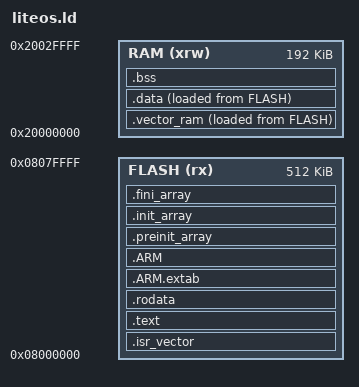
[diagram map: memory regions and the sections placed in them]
/*
******************************************************************************
**
**  File        : LinkerScript.ld
**
**  Author      : STM32CubeIDE
**
**  Abstract    : Linker script for STM32L552xE Device from STM32L5 series
**                      512Kbytes FLASH
**                      192Kbytes RAM
**
**                Set heap size, stack size and stack location according
**                to application requirements.
**
**                Set memory bank area and size if external memory is used.
**
**  Target      : STMicroelectronics STM32
**
**  Distribution: The file is distributed as is without any warranty
**                of any kind.
**
*****************************************************************************
** @attention
**
** <h2><center>&copy; Copyright (c) 2020 STMicroelectronics.
** All rights reserved.</center></h2>
**
** This software component is licensed by ST under BSD 3-Clause license,
** the "License"; You may not use this file except in compliance with the
** License. You may obtain a copy of the License at:
**                        opensource.org/licenses/BSD-3-Clause
**
*****************************************************************************
*/

/* Entry Point */
ENTRY(Reset_Handler)

/* Highest address of the user mode stack */
_estack = ORIGIN(RAM) + LENGTH(RAM);  /* end of "RAM" Ram type memory */

_Min_Stack_Size = 0x400;    /* required amount of stack */

/* Memories definition */
MEMORY
{
  RAM (xrw) : ORIGIN = 0x20000000,  LENGTH = 192K
  FLASH (rx)  : ORIGIN = 0x8000000, LENGTH = 512K
}

/* Sections */
SECTIONS
{
  /* The startup code into "FLASH" Rom type memory */
  .isr_vector :
  {
    . = ALIGN(4);
    KEEP(*(.isr_vector)) /* Startup code */
    . = ALIGN(4);
  } >FLASH

  /* The program code and other data into "FLASH" Rom type memory */
  .text :
  {
    . = ALIGN(4);
    __text_start = .;
    *(.text)           /* .text sections (code) */
    *(.text*)          /* .text* sections (code) */
    *(.glue_7)         /* glue arm to thumb code */
    *(.glue_7t)        /* glue thumb to arm code */
    *(.eh_frame)

    KEEP (*(.init))
    KEEP (*(.fini))

    . = ALIGN(4);
    _etext = .;        /* define a global symbols at end of code */
    __text_end = _etext;
  } >FLASH

  /* Constant data into "FLASH" Rom type memory */
  .rodata :
  {
    . = ALIGN(4);
    __rodata_start = .;

    *(.rodata)         /* .rodata sections (constants, strings, etc.) */
    *(.rodata*)        /* .rodata* sections (constants, strings, etc.) */
    . = ALIGN(4);
    __rodata_end = .;
  } >FLASH

  .ARM.extab   : {
    . = ALIGN(4);
    *(.ARM.extab* .gnu.linkonce.armextab.*)
    . = ALIGN(4);
  } >FLASH

  .ARM : {
    . = ALIGN(4);
    __exidx_start = .;
    *(.ARM.exidx*)
    __exidx_end = .;
    . = ALIGN(4);
  } >FLASH

  .preinit_array     :
  {
    . = ALIGN(4);
    PROVIDE_HIDDEN (__preinit_array_start = .);
    KEEP (*(.preinit_array*))
    PROVIDE_HIDDEN (__preinit_array_end = .);
    . = ALIGN(4);
  } >FLASH

  .init_array :
  {
    . = ALIGN(4);
    PROVIDE_HIDDEN (__init_array_start = .);
    KEEP (*(SORT(.init_array.*)))
    KEEP (*(.init_array*))
    PROVIDE_HIDDEN (__init_array_end = .);
    . = ALIGN(4);
  } >FLASH

  .fini_array :
  {
    . = ALIGN(4);
    PROVIDE_HIDDEN (__fini_array_start = .);
    KEEP (*(SORT(.fini_array.*)))
    KEEP (*(.fini_array*))
    PROVIDE_HIDDEN (__fini_array_end = .);
    . = ALIGN(4);
  } >FLASH

  /* used by the startup to initialize liteos vector */
  _si_liteos_vector_data = LOADADDR(.vector_ram);

  /* Initialized liteos vector sections goes into RAM, load LMA copy after code */
  .vector_ram :
  {
    . = ORIGIN(RAM);
    _s_liteos_vector = .;
    *(.data.vector)    /* liteos vector in ram */
    _e_liteos_vector = .;
  } > RAM AT> FLASH

  /* Used by the startup to initialize data */
  _sidata = LOADADDR(.data);

  /* Initialized data sections into "RAM" Ram type memory */
  .data ALIGN(0x1000):
  {
    __ram_data_start = _sdata;
    . = ALIGN(4);
    _sdata = .;        /* create a global symbol at data start */
    *(.data)           /* .data sections */
    *(.data*)          /* .data* sections */
    *(.RamFunc)        /* .RamFunc sections */
    *(.RamFunc*)       /* .RamFunc* sections */
    KEEP(*( SORT (.liteos.table.*)));

    . = ALIGN(4);
    _edata = .;        /* define a global symbol at data end */
    __ram_data_end = _edata;
  } >RAM AT> FLASH

  /* Uninitialized data section into "RAM" Ram type memory */
  . = ALIGN(4);
  .bss :
  {
    /* This is used by the startup in order to initialize the .bss section */
    _sbss = .;         /* define a global symbol at bss start */
    __bss_start__ = _sbss;
    __bss_start = _sbss;
    *(.bss)
    *(.bss*)
    *(COMMON)

    . = ALIGN(4);
    _ebss = .;         /* define a global symbol at bss end */
    __bss_end__ = _ebss;
    __bss_end = _ebss;
  } >RAM

  . = ALIGN(8);
  __los_heap_addr_start__ = .;
  __los_heap_addr_end__ = ORIGIN(RAM) + LENGTH(RAM) - _Min_Stack_Size - 1;

  __fast_end = .;
  
  /* Remove information from the compiler libraries */
  /DISCARD/ :
  {
    libc.a ( * )
    libm.a ( * )
    libgcc.a ( * )
  }

  .ARM.attributes 0 : { *(.ARM.attributes) }
}
